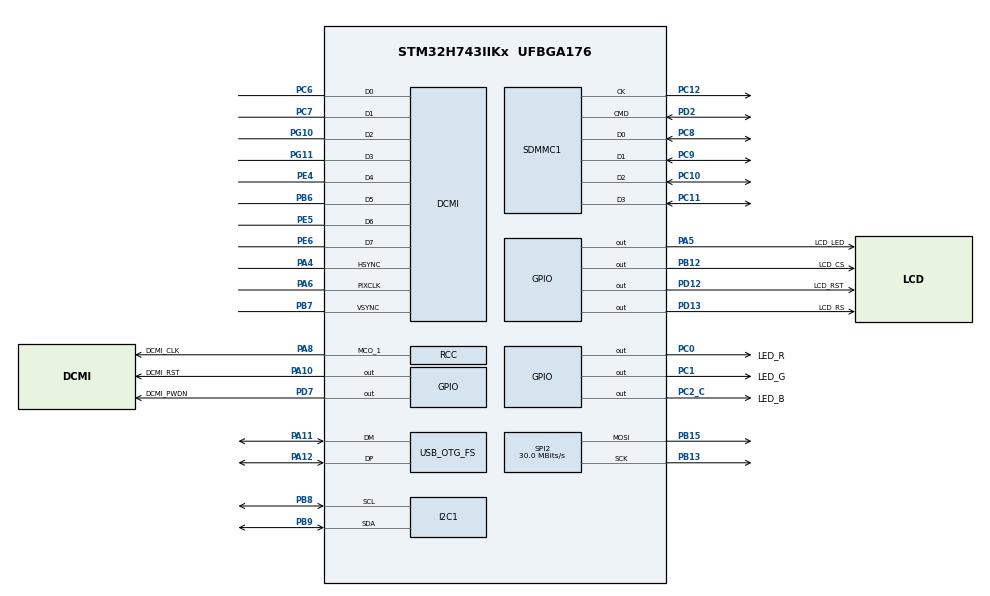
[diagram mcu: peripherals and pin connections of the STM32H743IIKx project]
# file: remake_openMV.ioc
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DCMI.JPEGMode=DCMI_JPEG_ENABLE
DCMI.PCKPolarity=DCMI_PCKPOLARITY_RISING
Dma.DCMI.1.Direction=DMA_PERIPH_TO_MEMORY
Dma.DCMI.1.EventEnable=DISABLE
Dma.DCMI.1.FIFOMode=DMA_FIFOMODE_ENABLE
Dma.DCMI.1.FIFOThreshold=DMA_FIFO_THRESHOLD_HALFFULL
Dma.DCMI.1.Instance=DMA1_Stream1
Dma.DCMI.1.MemBurst=DMA_MBURST_SINGLE
Dma.DCMI.1.MemDataAlignment=DMA_MDATAALIGN_WORD
Dma.DCMI.1.MemInc=DMA_MINC_ENABLE
Dma.DCMI.1.Mode=DMA_CIRCULAR
Dma.DCMI.1.PeriphBurst=DMA_PBURST_SINGLE
Dma.DCMI.1.PeriphDataAlignment=DMA_PDATAALIGN_WORD
Dma.DCMI.1.PeriphInc=DMA_PINC_DISABLE
Dma.DCMI.1.Polarity=HAL_DMAMUX_REQ_GEN_RISING
Dma.DCMI.1.Priority=DMA_PRIORITY_LOW
Dma.DCMI.1.RequestNumber=1
Dma.DCMI.1.SignalID=NONE
Dma.DCMI.1.SyncEnable=DISABLE
Dma.DCMI.1.SyncPolarity=HAL_DMAMUX_SYNC_NO_EVENT
Dma.DCMI.1.SyncRequestNumber=1
Dma.DCMI.1.SyncSignalID=NONE
Dma.Request0=SPI2_TX
Dma.Request1=DCMI
Dma.SPI2_TX.0.Direction=DMA_MEMORY_TO_PERIPH
Dma.SPI2_TX.0.EventEnable=DISABLE
Dma.SPI2_TX.0.FIFOMode=DMA_FIFOMODE_DISABLE
Dma.SPI2_TX.0.Instance=DMA1_Stream5
Dma.SPI2_TX.0.MemDataAlignment=DMA_MDATAALIGN_HALFWORD
Dma.SPI2_TX.0.MemInc=DMA_MINC_ENABLE
Dma.SPI2_TX.0.Mode=DMA_NORMAL
Dma.SPI2_TX.0.PeriphDataAlignment=DMA_PDATAALIGN_HALFWORD
Dma.SPI2_TX.0.PeriphInc=DMA_PINC_DISABLE
Dma.SPI2_TX.0.Polarity=HAL_DMAMUX_REQ_GEN_RISING
Dma.SPI2_TX.0.Priority=DMA_PRIORITY_LOW
Dma.SPI2_TX.0.RequestNumber=1
Dma.SPI2_TX.0.SignalID=NONE
Dma.SPI2_TX.0.SyncEnable=DISABLE
Dma.SPI2_TX.0.SyncPolarity=HAL_DMAMUX_SYNC_NO_EVENT
Dma.SPI2_TX.0.SyncRequestNumber=1
Dma.SPI2_TX.0.SyncSignalID=NONE
FATFS._CODE_PAGE=936
FATFS._USE_LABEL=1
FATFS._USE_LFN=2
I2C1.Timing=0x109093DC
Mcu.Family=STM32H7
Mcu.Name=STM32H743IIKx
Mcu.Package=UFBGA176
NVIC.DCMI_IRQn=true\:1\:0\:true\:false\:true\:true\:true\:true
NVIC.DMA1_Stream1_IRQn=true\:2\:0\:true\:false\:true\:false\:true\:true
NVIC.DMA1_Stream5_IRQn=true\:6\:0\:true\:false\:true\:false\:true\:true
NVIC.HSEM1_IRQn=true\:0\:0\:false\:false\:true\:true\:true\:true
NVIC.OTG_FS_IRQn=true\:0\:0\:true\:false\:true\:true\:true\:true
NVIC.PriorityGroup=NVIC_PRIORITYGROUP_4
NVIC.SPI2_IRQn=true\:5\:0\:true\:false\:true\:true\:true\:true
PA10.GPIO_Label=DCMI_RST
PA10.GPIO_PuPd=GPIO_PULLUP
PA10.PinState=GPIO_PIN_SET
PA10.Signal=GPIO_Output
PA11.GPIO_Speed=GPIO_SPEED_FREQ_HIGH
PA11.Mode=Device_Only
PA11.Signal=USB_OTG_FS_DM
PA12.GPIO_Speed=GPIO_SPEED_FREQ_HIGH
PA12.Mode=Device_Only
PA12.Signal=USB_OTG_FS_DP
PA13\ (JTMS/SWDIO).Mode=Serial_Wire
PA13\ (JTMS/SWDIO).Signal=DEBUG_JTMS-SWDIO
PA14\ (JTCK/SWCLK).Mode=Serial_Wire
PA14\ (JTCK/SWCLK).Signal=DEBUG_JTCK-SWCLK
PA4.Mode=Slave_8_bits_External_Synchro
PA4.Signal=DCMI_HSYNC
PA5.GPIO_Label=LCD_LED
PA5.Signal=GPIO_Output
PA6.Mode=Slave_8_bits_External_Synchro
PA6.Signal=DCMI_PIXCLK
PA8.GPIO_Label=DCMI_CLK
PA8.GPIO_Speed=GPIO_SPEED_FREQ_VERY_HIGH
PA8.Mode=Clock-out-1
PA8.Signal=RCC_MCO_1
PB12.GPIO_Label=LCD_CS
PB12.Signal=GPIO_Output
PB13.Mode=TX_Only_Simplex_Unidirect_Master
PB13.Signal=SPI2_SCK
PB15.Mode=TX_Only_Simplex_Unidirect_Master
PB15.Signal=SPI2_MOSI
PB6.Mode=Slave_8_bits_External_Synchro
PB6.Signal=DCMI_D5
PB7.Mode=Slave_8_bits_External_Synchro
PB7.Signal=DCMI_VSYNC
PB8.Mode=I2C
PB8.Signal=I2C1_SCL
PB9.Mode=I2C
PB9.Signal=I2C1_SDA
PC0.GPIO_Label=LED_R
PC0.PinState=GPIO_PIN_SET
PC0.Signal=GPIO_Output
PC1.GPIO_Label=LED_G
PC1.PinState=GPIO_PIN_SET
PC1.Signal=GPIO_Output
PC10.Mode=SD_4_bits_Wide_bus
PC10.Signal=SDMMC1_D2
PC11.Mode=SD_4_bits_Wide_bus
PC11.Signal=SDMMC1_D3
PC12.Mode=SD_4_bits_Wide_bus
PC12.Signal=SDMMC1_CK
PC2_C.GPIO_Label=LED_B
PC2_C.PinState=GPIO_PIN_SET
PC2_C.Signal=GPIO_Output
PC6.Mode=Slave_8_bits_External_Synchro
PC6.Signal=DCMI_D0
PC7.Mode=Slave_8_bits_External_Synchro
PC7.Signal=DCMI_D1
PC8.Mode=SD_4_bits_Wide_bus
PC8.Signal=SDMMC1_D0
PC9.Mode=SD_4_bits_Wide_bus
PC9.Signal=SDMMC1_D1
PD12.GPIO_Label=LCD_RST
PD12.Signal=GPIO_Output
PD13.GPIO_Label=LCD_RS
PD13.Signal=GPIO_Output
PD2.Mode=SD_4_bits_Wide_bus
PD2.Signal=SDMMC1_CMD
PD7.GPIO_Label=DCMI_PWDN
PD7.GPIO_PuPd=GPIO_PULLUP
PD7.PinState=GPIO_PIN_SET
PD7.Signal=GPIO_Output
PE4.Mode=Slave_8_bits_External_Synchro
PE4.Signal=DCMI_D4
PE5.Mode=Slave_8_bits_External_Synchro
PE5.Signal=DCMI_D6
PE6.Mode=Slave_8_bits_External_Synchro
PE6.Signal=DCMI_D7
PG10.Mode=Slave_8_bits_External_Synchro
PG10.Signal=DCMI_D2
PG11.Mode=Slave_8_bits_External_Synchro
PG11.Signal=DCMI_D3
PH0-OSC_IN\ (PH0).Mode=HSE-External-Oscillator
PH0-OSC_IN\ (PH0).Signal=RCC_OSC_IN
PH1-OSC_OUT\ (PH1).Mode=HSE-External-Oscillator
PH1-OSC_OUT\ (PH1).Signal=RCC_OSC_OUT
ProjectManager.HeapSize=0x2000
ProjectManager.StackSize=0x4000
ProjectManager.TargetToolchain=STM32CubeIDE
RCC.ADCFreq_Value=150000000
RCC.APB1Freq_Value=120000000
RCC.APB2Freq_Value=120000000
RCC.APB3Freq_Value=120000000
RCC.APB4Freq_Value=120000000
RCC.CKPERSourceSelection=RCC_CLKPSOURCE_HSE
RCC.CortexFreq_Value=480000000
RCC.D1PPRE=RCC_APB3_DIV2
RCC.D2PPRE1=RCC_APB1_DIV2
RCC.D2PPRE2=RCC_APB2_DIV2
RCC.D3PPRE=RCC_APB4_DIV2
RCC.DIVM1=3
RCC.DIVM2=1
RCC.DIVM3=1
RCC.DIVN1=240
RCC.DIVN2=12
RCC.DIVN3=12
RCC.DIVP2=1
RCC.DIVQ1=8
RCC.DIVQ3=3
RCC.DIVR1=8
RCC.HCLKFreq_Value=240000000
RCC.HPRE=RCC_HCLK_DIV2
RCC.HSE_VALUE=12000000
RCC.I2C123CLockSelection=RCC_I2C123CLKSOURCE_PLL3
RCC.PLL2FRACN=4096
RCC.PLL3FRACN=4096
RCC.PLLFRACN=0
RCC.PLLSourceVirtual=RCC_PLLSOURCE_HSE
RCC.ProductRev=revV
RCC.RCC_MCO1Source=RCC_MCO1SOURCE_HSI48
RCC.SYSCLKFreq_VALUE=480000000
RCC.SYSCLKSource=RCC_SYSCLKSOURCE_PLLCLK
RCC.USBCLockSelection=RCC_USBCLKSOURCE_HSI48
RCC.USBFreq_Value=48000000
SDMMC1.ClockDiv=4
SPI2.BaudRatePrescaler=SPI_BAUDRATEPRESCALER_4
SPI2.CalculateBaudRate=30.0 MBits/s
SPI2.DataSize=SPI_DATASIZE_8BIT
SPI2.Direction=SPI_DIRECTION_2LINES_TXONLY
SPI2.Mode=SPI_MODE_MASTER
SPI2.VirtualType=VM_MASTER
USB_DEVICE.CLASS_NAME_FS=MSC
USB_DEVICE.MSC_MEDIA_PACKET-MSC_FS=32768
USB_DEVICE.VirtualMode-MSC_FS=Msc
USB_DEVICE.VirtualModeFS=Msc_FS
USB_OTG_FS.VirtualMode=Device_Only
VP_FATFS_VS_Generic.Mode=User_defined
VP_USB_DEVICE_VS_USB_DEVICE_MSC_FS.Mode=MSC_FS
board=custom

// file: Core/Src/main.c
/* USER CODE BEGIN Header */
/**
  ******************************************************************************
  * @file           : main.c
  * @brief          : Main program body
  ******************************************************************************
  * @attention
  *
  * Copyright (c) 2023 STMicroelectronics.
  * All rights reserved.
  *
  * This software is licensed under terms that can be found in the LICENSE file
  * in the root directory of this software component.
  * If no LICENSE file comes with this software, it is provided AS-IS.
  *
  ******************************************************************************
  */
/* USER CODE END Header */
#include "main.h"
#include "dcmi.h"
#include "dma.h"
#include "fatfs.h"
#include "i2c.h"
#include "sdmmc.h"
#include "spi.h"
#include "usb_device.h"
#include "gpio.h"

/* USER CODE BEGIN Includes */
#include "lcd_display.h"
#include "file_system.h"
#include "usb_vcp.h"
#include "camera_run.h"
/* USER CODE END Includes */

void SystemClock_Config(void);

int main(void)
{

  /* MCU Configuration--------------------------------------------------------*/

  /* Reset of all peripherals, Initializes the Flash interface and the Systick. */
  HAL_Init();

  /* Configure the system clock */
  SystemClock_Config();

  /* Initialize all configured peripherals */
  MX_GPIO_Init();
  MX_DMA_Init();
  MX_SPI2_Init();
  MX_USB_DEVICE_Init();
  MX_SDMMC1_SD_Init();
  MX_FATFS_Init();
  MX_DCMI_Init();
  MX_I2C1_Init();
  /* USER CODE BEGIN 2 */
  lcd_init();
  FatFs_read_Check();
  FatFs_write_Check();
  camera_RGB565_init();
//  camera_JPEG_init();

  /* USER CODE END 2 */

  /* Infinite loop */
  while (1)
  {

    /* USER CODE BEGIN 3 */
//	  HAL_GPIO_TogglePin(LED_R_GPIO_Port,LED_R_Pin);
//	  HAL_Delay(500);
//	  HAL_GPIO_TogglePin(LED_G_GPIO_Port,LED_G_Pin);
//	  HAL_Delay(500);
//	  HAL_GPIO_TogglePin(LED_B_GPIO_Port,LED_B_Pin);
//	  HAL_Delay(500);
//	  usb_printf("openmv4 plus board cdc test\r\n");
	  TFT_LCD_RGB565_run();
//	  JPEG_run();
  }
  /* USER CODE END 3 */
}

void SystemClock_Config(void)
{
  RCC_OscInitTypeDef RCC_OscInitStruct = {0};
  RCC_ClkInitTypeDef RCC_ClkInitStruct = {0};

  /** Supply configuration update enable
  */
  HAL_PWREx_ConfigSupply(PWR_LDO_SUPPLY);

  /** Configure the main internal regulator output voltage
  */
  __HAL_PWR_VOLTAGESCALING_CONFIG(PWR_REGULATOR_VOLTAGE_SCALE1);

  while(!__HAL_PWR_GET_FLAG(PWR_FLAG_VOSRDY)) {}

  __HAL_RCC_SYSCFG_CLK_ENABLE();
  __HAL_PWR_VOLTAGESCALING_CONFIG(PWR_REGULATOR_VOLTAGE_SCALE0);

  while(!__HAL_PWR_GET_FLAG(PWR_FLAG_VOSRDY)) {}

  /** Initializes the RCC Oscillators according to the specified parameters
  * in the RCC_OscInitTypeDef structure.
  */
  RCC_OscInitStruct.OscillatorType = RCC_OSCILLATORTYPE_HSI48|RCC_OSCILLATORTYPE_HSE;
  RCC_OscInitStruct.HSEState = RCC_HSE_ON;
  RCC_OscInitStruct.HSI48State = RCC_HSI48_ON;
  RCC_OscInitStruct.PLL.PLLState = RCC_PLL_ON;
  RCC_OscInitStruct.PLL.PLLSource = RCC_PLLSOURCE_HSE;
  RCC_OscInitStruct.PLL.PLLM = 3;
  RCC_OscInitStruct.PLL.PLLN = 240;
  RCC_OscInitStruct.PLL.PLLP = 2;
  RCC_OscInitStruct.PLL.PLLQ = 8;
  RCC_OscInitStruct.PLL.PLLR = 8;
  RCC_OscInitStruct.PLL.PLLRGE = RCC_PLL1VCIRANGE_2;
  RCC_OscInitStruct.PLL.PLLVCOSEL = RCC_PLL1VCOWIDE;
  RCC_OscInitStruct.PLL.PLLFRACN = 0;
  if (HAL_RCC_OscConfig(&RCC_OscInitStruct) != HAL_OK)
  {
    Error_Handler();
  }

  /** Initializes the CPU, AHB and APB buses clocks
  */
  RCC_ClkInitStruct.ClockType = RCC_CLOCKTYPE_HCLK|RCC_CLOCKTYPE_SYSCLK
                              |RCC_CLOCKTYPE_PCLK1|RCC_CLOCKTYPE_PCLK2
                              |RCC_CLOCKTYPE_D3PCLK1|RCC_CLOCKTYPE_D1PCLK1;
  RCC_ClkInitStruct.SYSCLKSource = RCC_SYSCLKSOURCE_PLLCLK;
  RCC_ClkInitStruct.SYSCLKDivider = RCC_SYSCLK_DIV1;
  RCC_ClkInitStruct.AHBCLKDivider = RCC_HCLK_DIV2;
  RCC_ClkInitStruct.APB3CLKDivider = RCC_APB3_DIV2;
  RCC_ClkInitStruct.APB1CLKDivider = RCC_APB1_DIV2;
  RCC_ClkInitStruct.APB2CLKDivider = RCC_APB2_DIV2;
  RCC_ClkInitStruct.APB4CLKDivider = RCC_APB4_DIV2;

  if (HAL_RCC_ClockConfig(&RCC_ClkInitStruct, FLASH_LATENCY_4) != HAL_OK)
  {
    Error_Handler();
  }
  HAL_RCC_MCOConfig(RCC_MCO1, RCC_MCO1SOURCE_HSI48, RCC_MCODIV_1);
}

void Error_Handler(void)
{
  __disable_irq();
  while (1)
  {
  }
}
